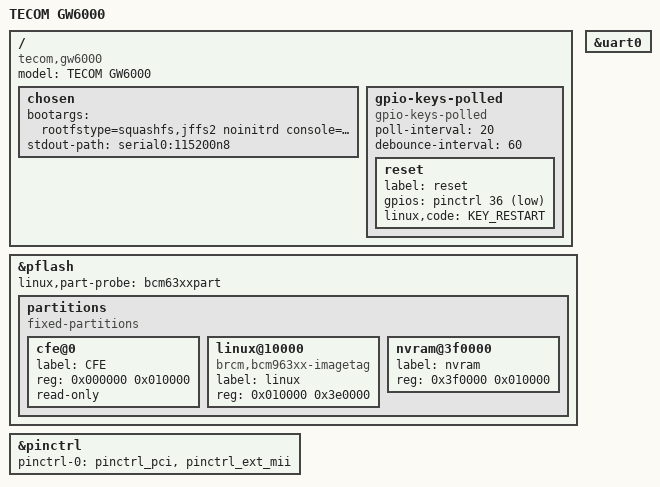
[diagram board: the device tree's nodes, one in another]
/dts-v1/;

#include "bcm6348.dtsi"

#include <dt-bindings/input/input.h>

/ {
	model = "TECOM GW6000";
	compatible = "tecom,gw6000", "brcm,bcm6348";

	chosen {
		bootargs = "rootfstype=squashfs,jffs2 noinitrd console=ttyS0,115200";
		stdout-path = "serial0:115200n8";
	};

	gpio-keys-polled {
		compatible = "gpio-keys-polled";
		#address-cells = <1>;
		#size-cells = <0>;
		poll-interval = <20>;
		debounce-interval = <60>;

		reset {
			label = "reset";
			gpios = <&pinctrl 36 1>;
			linux,code = <KEY_RESTART>;
		};
	};
};

&pflash {
	status = "ok";

	linux,part-probe = "bcm63xxpart";

	partitions {
		compatible = "fixed-partitions";
		#address-cells = <1>;
		#size-cells = <1>;

		cfe@0 {
			label = "CFE";
			reg = <0x000000 0x010000>;
			read-only;
		};

		linux@10000 {
			label = "linux";
			reg = <0x010000 0x3e0000>;
			compatible = "brcm,bcm963xx-imagetag";
		};

		nvram@3f0000 {
			label = "nvram";
			reg = <0x3f0000 0x010000>;
		};
	};
};

&pinctrl {
	pinctrl-names = "default";
	pinctrl-0 = <&pinctrl_pci &pinctrl_ext_mii>;
};

&uart0 {
	status = "ok";
};
